# EFR32FG1V131F256GM48 register map
File version: 3.0.0
CPU: CM4 r0p1, little endian, MPU, FPU, 3 interrupt priority bits
Registers are 32-bit, read-write, reset 0x0 unless marked. A register's access mark holds for its fields unless they carry their own. Offsets are from the block's base; [hi:lo] are bit positions; {n}, {i} and the like mark numbered series; 'fields as' and 'values as' point back to an identical list.

## MODEM — Modem controller
Base 0x40086000
Same registers: MODEM_CLR 0x44086000, MODEM_SET 0x46086000
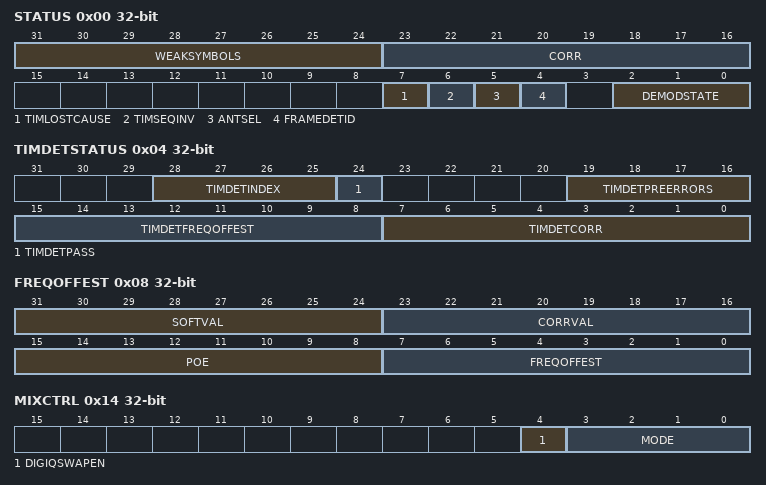
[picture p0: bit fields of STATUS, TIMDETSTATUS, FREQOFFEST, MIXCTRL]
0x00 STATUS ro
  [31:24] WEAKSYMBOLS, [23:16] CORR, [7] TIMLOSTCAUSE, [6] TIMSEQINV, [5] ANTSEL, [4] FRAMEDETID, [2:0] DEMODSTATE
0x04 TIMDETSTATUS ro
  [28:25] TIMDETINDEX, [24] TIMDETPASS, [19:16] TIMDETPREERRORS, [15:8] TIMDETFREQOFFEST, [7:0] TIMDETCORR
0x08 FREQOFFEST ro
  [31:24] SOFTVAL, [23:16] CORRVAL, [15:8] POE, [7:0] FREQOFFEST
0x0C AFCADJRX ro
  [18:0] AFCADJRX
0x10 AFCADJTX ro
  [18:0] AFCADJTX
0x14 MIXCTRL
  [4] DIGIQSWAPEN, [3:0] MODE
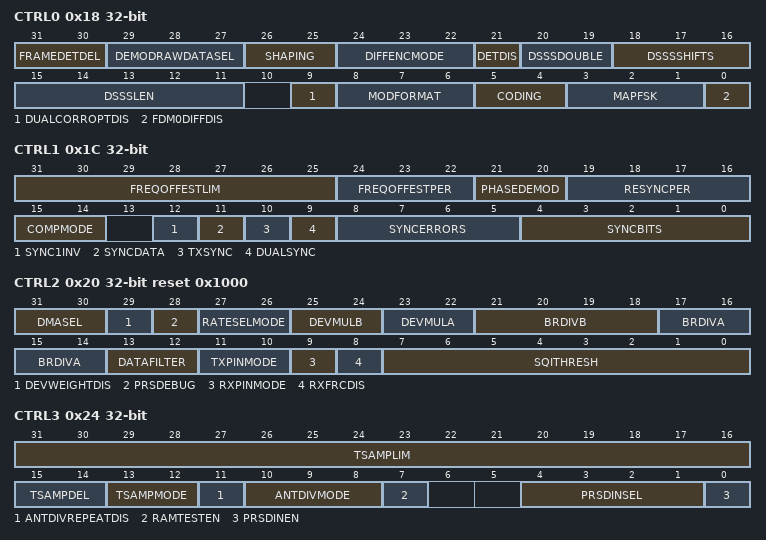
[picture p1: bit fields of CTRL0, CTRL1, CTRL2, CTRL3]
0x18 CTRL0
  [31:30] FRAMEDETDEL, [29:27] DEMODRAWDATASEL, [26:25] SHAPING, [24:22] DIFFENCMODE, [21] DETDIS, [20:19] DSSSDOUBLE, [18:16] DSSSSHIFTS, [15:11] DSSSLEN, [9] DUALCORROPTDIS, [8:6] MODFORMAT, [5:4] CODING, [3:1] MAPFSK, [0] FDM0DIFFDIS
0x1C CTRL1
  [31:25] FREQOFFESTLIM, [24:22] FREQOFFESTPER, [21:20] PHASEDEMOD, [19:16] RESYNCPER, [15:14] COMPMODE, [12] SYNC1INV, [11] SYNCDATA, [10] TXSYNC, [9] DUALSYNC, [8:5] SYNCERRORS, [4:0] SYNCBITS
0x20 CTRL2 reset 0x1000
  [31:30] DMASEL, [29] DEVWEIGHTDIS, [28] PRSDEBUG, [27:26] RATESELMODE, [25:24] DEVMULB, [23:22] DEVMULA, [21:18] BRDIVB, [17:14] BRDIVA, [13:12] DATAFILTER, [11:10] TXPINMODE, [9] RXPINMODE, [8] RXFRCDIS, [7:0] SQITHRESH
0x24 CTRL3
  [31:16] TSAMPLIM, [15:14] TSAMPDEL, [13:12] TSAMPMODE, [11] ANTDIVREPEATDIS, [10:8] ANTDIVMODE, [7] RAMTESTEN, [4:1] PRSDINSEL, [0] PRSDINEN
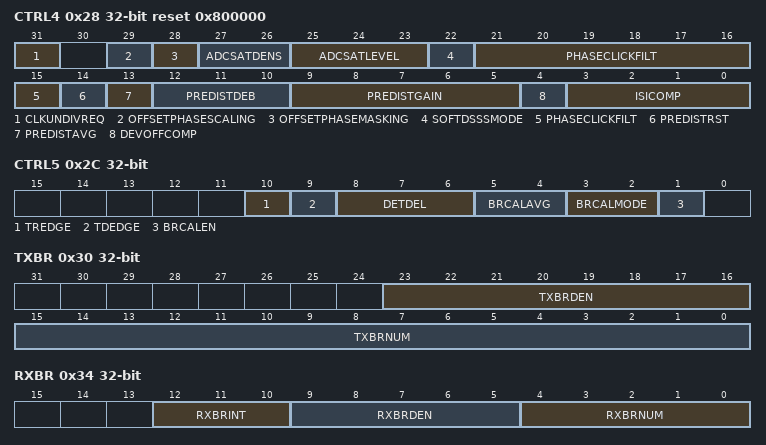
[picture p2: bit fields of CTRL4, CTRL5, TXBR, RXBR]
0x28 CTRL4 reset 0x800000
  [31] CLKUNDIVREQ, [29] OFFSETPHASESCALING, [28] OFFSETPHASEMASKING, [27:26] ADCSATDENS, [25:23] ADCSATLEVEL, [22] SOFTDSSSMODE, [21:15] PHASECLICKFILT, [14] PREDISTRST, [13] PREDISTAVG, [12:10] PREDISTDEB, [9:5] PREDISTGAIN, [4] DEVOFFCOMP, [3:0] ISICOMP
0x2C CTRL5
  [10] TREDGE, [9] TDEDGE, [8:6] DETDEL, [5:4] BRCALAVG, [3:2] BRCALMODE, [1] BRCALEN
0x30 TXBR
  [23:16] TXBRDEN, [15:0] TXBRNUM
0x34 RXBR
  [12:10] RXBRINT, [9:5] RXBRDEN, [4:0] RXBRNUM
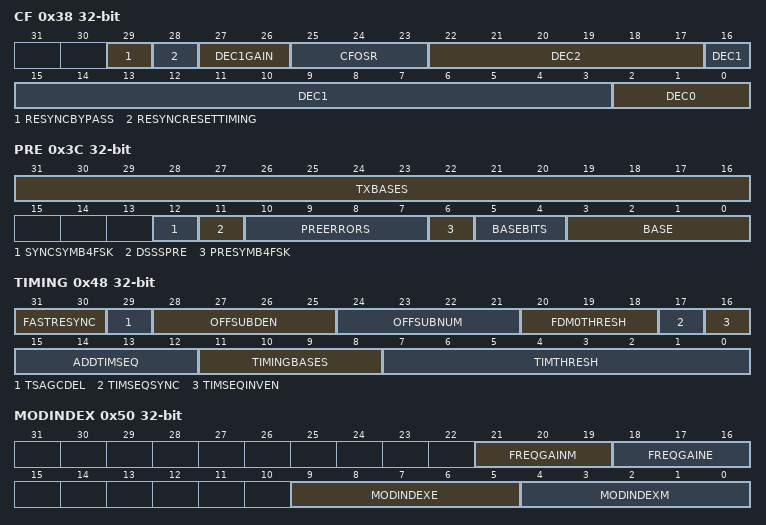
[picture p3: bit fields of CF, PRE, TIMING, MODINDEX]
0x38 CF
  [29] RESYNCBYPASS, [28] RESYNCRESETTIMING, [27:26] DEC1GAIN, [25:23] CFOSR, [22:17] DEC2, [16:3] DEC1, [2:0] DEC0
0x3C PRE
  [31:16] TXBASES, [12] SYNCSYMB4FSK, [11] DSSSPRE, [10:7] PREERRORS, [6] PRESYMB4FSK, [5:4] BASEBITS, [3:0] BASE
0x40 SYNC0
0x44 SYNC1
0x48 TIMING
  [31:30] FASTRESYNC, [29] TSAGCDEL, [28:25] OFFSUBDEN, [24:21] OFFSUBNUM, [20:18] FDM0THRESH, [17] TIMSEQSYNC, [16] TIMSEQINVEN, [15:12] ADDTIMSEQ, [11:8] TIMINGBASES, [7:0] TIMTHRESH
0x4C DSSS0
0x50 MODINDEX
  [21:19] FREQGAINM, [18:16] FREQGAINE, [9:5] MODINDEXE, [4:0] MODINDEXM
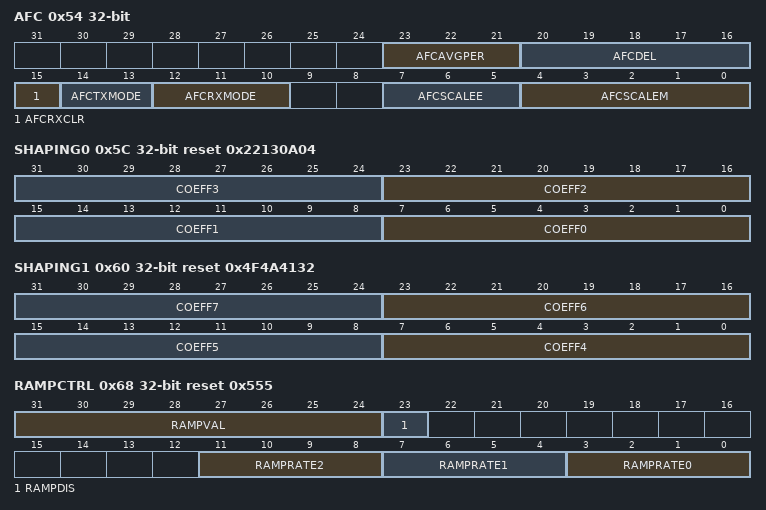
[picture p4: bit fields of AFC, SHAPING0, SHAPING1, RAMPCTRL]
0x54 AFC
  [23:21] AFCAVGPER, [20:16] AFCDEL, [15] AFCRXCLR, [14:13] AFCTXMODE, [12:10] AFCRXMODE, [7:5] AFCSCALEE, [4:0] AFCSCALEM
0x58 AFCADJLIM
  [17:0] AFCADJLIM
0x5C SHAPING0 reset 0x22130A04
  [8n+7:8n] COEFF{n} (n=0..3)
0x60 SHAPING1 reset 0x4F4A4132
  [8n-25:8n-32] COEFF{n} (n=4..7)
0x64 SHAPING2
  [7:0] COEFF8
0x68 RAMPCTRL reset 0x555
  [31:24] RAMPVAL, [23] RAMPDIS, [11:8] RAMPRATE2, [7:4] RAMPRATE1, [3:0] RAMPRATE0
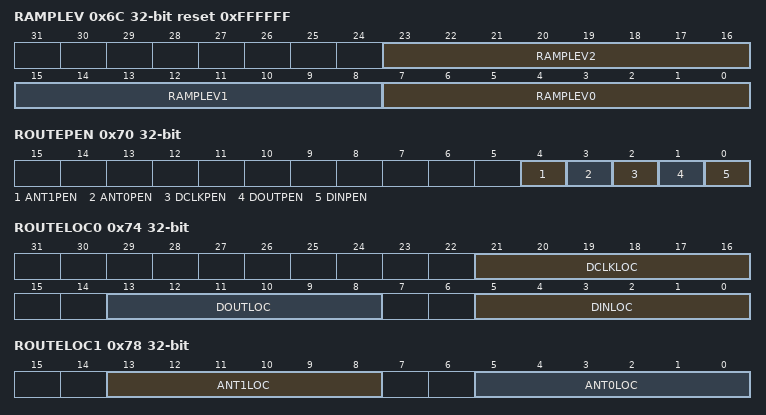
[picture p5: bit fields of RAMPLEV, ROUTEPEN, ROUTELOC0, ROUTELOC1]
0x6C RAMPLEV reset 0xFFFFFF
  [23:16] RAMPLEV2, [15:8] RAMPLEV1, [7:0] RAMPLEV0
0x70 ROUTEPEN
  [4] ANT1PEN, [3] ANT0PEN, [2] DCLKPEN, [1] DOUTPEN, [0] DINPEN
0x74 ROUTELOC0
  [21:16] DCLKLOC, [13:8] DOUTLOC, [5:0] DINLOC
0x78 ROUTELOC1
  [13:8] ANT1LOC, [5:0] ANT0LOC
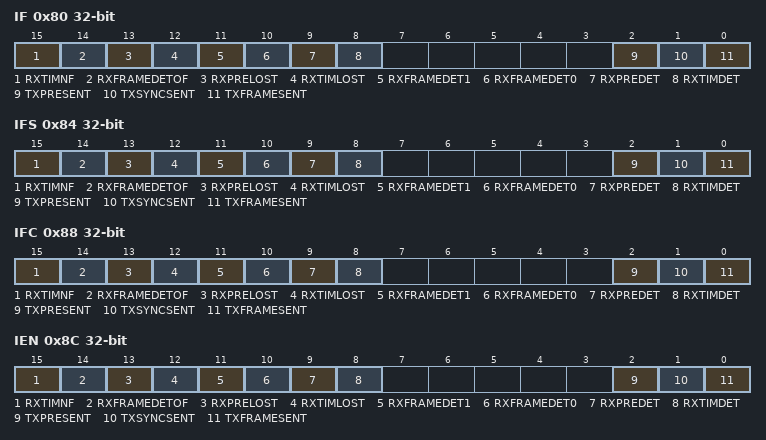
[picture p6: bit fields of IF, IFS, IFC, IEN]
0x80 IF ro
  [15] RXTIMNF, [14] RXFRAMEDETOF, [13] RXPRELOST, [12] RXTIMLOST, [11] RXFRAMEDET1, [10] RXFRAMEDET0, [9] RXPREDET, [8] RXTIMDET, [2] TXPRESENT, [1] TXSYNCSENT, [0] TXFRAMESENT
0x84 IFS wo
  fields as IF
0x88 IFC wo
  fields as IF
0x8C IEN
  fields as IF
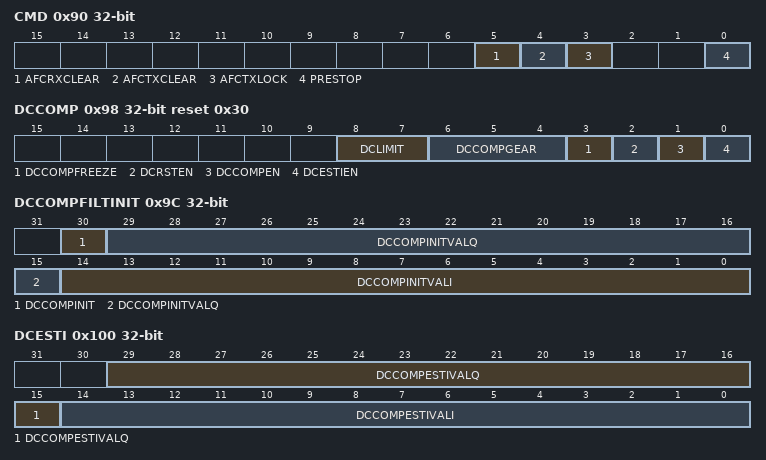
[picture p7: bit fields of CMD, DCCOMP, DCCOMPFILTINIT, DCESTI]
0x90 CMD wo
  [5] AFCRXCLEAR, [4] AFCTXCLEAR, [3] AFCTXLOCK, [0] PRESTOP
0x98 DCCOMP reset 0x30
  [8:7] DCLIMIT, [6:4] DCCOMPGEAR, [3] DCCOMPFREEZE, [2] DCRSTEN, [1] DCCOMPEN, [0] DCESTIEN
0x9C DCCOMPFILTINIT
  [30] DCCOMPINIT, [29:15] DCCOMPINITVALQ, [14:0] DCCOMPINITVALI
0x100 DCESTI ro
  [29:15] DCCOMPESTIVALQ, [14:0] DCCOMPESTIVALI
{0x400+4i} RAM{i}_RAMDATA (i=0..255)
  [7:0] DATA
